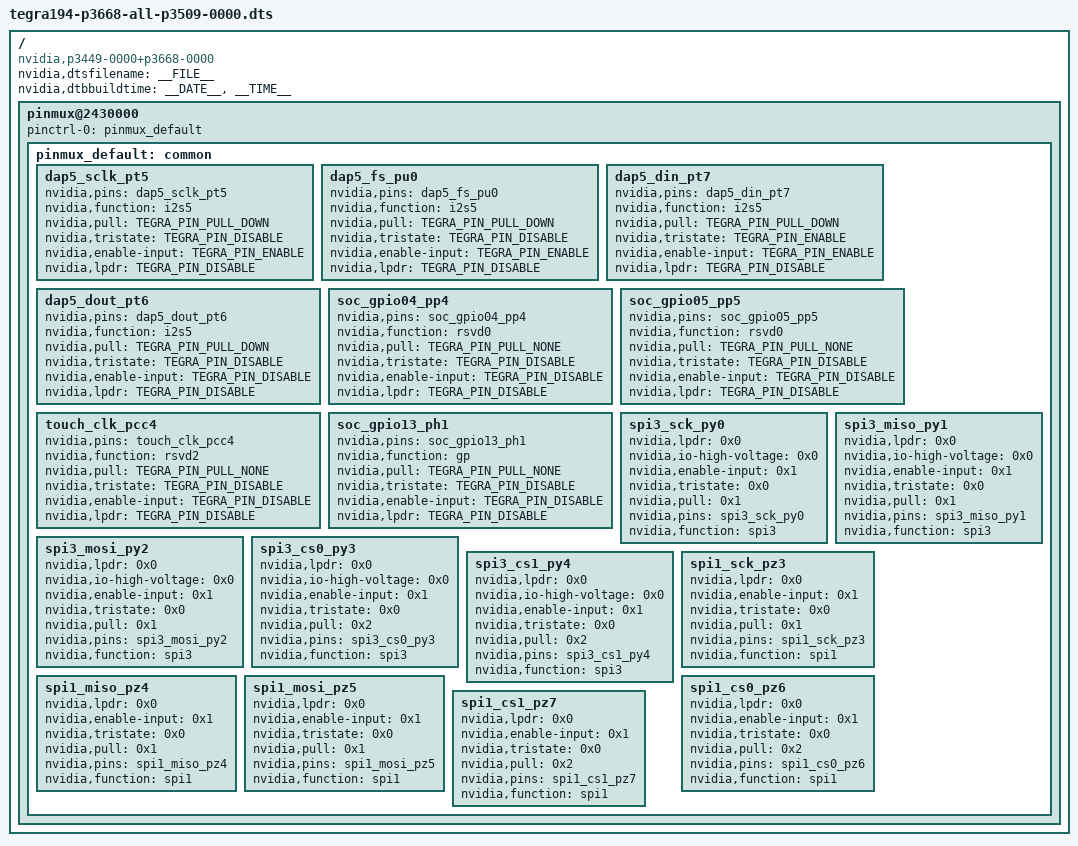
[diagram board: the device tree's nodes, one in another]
/*
 * Top level DTS file for CVM:P3668-0001 and CVB:P3509-0000.
 *
 * Copyright (c) 2019-2020, NVIDIA CORPORATION.  All rights reserved.
 *
 * This program is free software; you can redistribute it and/or modify
 * it under the terms of the GNU General Public License as published by
 * the Free Software Foundation; version 2 of the License.
 *
 * This program is distributed in the hope that it will be useful, but WITHOUT
 * ANY WARRANTY; without even the implied warranty of MERCHANTABILITY or
 * FITNESS FOR A PARTICULAR PURPOSE.  See the GNU General Public License for
 * more details.
 */

/dts-v1/;
#include "common/tegra194-p3668-common.dtsi"
#include "common/tegra194-p3509-0000-a00.dtsi"

/ {
	nvidia,dtsfilename = __FILE__;
	nvidia,dtbbuildtime = __DATE__, __TIME__;

	compatible = "nvidia,p3449-0000+p3668-0000", "nvidia,p3449-0000+p3668-0001", "nvidia,p3509-0000+p3668-0000", "nvidia,p3509-0000+p3668-0001", "nvidia,tegra194";
};

/* For EAC-2000, Why at here */
/ {
	
	pinmux@2430000 {
		pinctrl-names = "default", "drive", "unused";
		pinctrl-0 = <&pinmux_default>;
		
		pinmux_default: common {
			/* I2C0 (dap5 group) at Key E */
			dap5_sclk_pt5 {
				nvidia,pins = "dap5_sclk_pt5";
				nvidia,function = "i2s5";
				nvidia,pull = <TEGRA_PIN_PULL_DOWN>;
				nvidia,tristate = <TEGRA_PIN_DISABLE>;
				nvidia,enable-input = <TEGRA_PIN_ENABLE>;
				nvidia,lpdr = <TEGRA_PIN_DISABLE>;
			};

			dap5_fs_pu0 {
				nvidia,pins = "dap5_fs_pu0";
				nvidia,function = "i2s5";
				nvidia,pull = <TEGRA_PIN_PULL_DOWN>;
				nvidia,tristate = <TEGRA_PIN_DISABLE>;
				nvidia,enable-input = <TEGRA_PIN_ENABLE>;
				nvidia,lpdr = <TEGRA_PIN_DISABLE>;
			};
				
			dap5_din_pt7 {
				nvidia,pins = "dap5_din_pt7";
				nvidia,function = "i2s5";
				nvidia,pull = <TEGRA_PIN_PULL_DOWN>;
				nvidia,tristate = <TEGRA_PIN_ENABLE>;
				nvidia,enable-input = <TEGRA_PIN_ENABLE>;
				nvidia,lpdr = <TEGRA_PIN_DISABLE>;
			};

			dap5_dout_pt6 {
				nvidia,pins = "dap5_dout_pt6";
				nvidia,function = "i2s5";
				nvidia,pull = <TEGRA_PIN_PULL_DOWN>;
				nvidia,tristate = <TEGRA_PIN_DISABLE>;
				nvidia,enable-input = <TEGRA_PIN_DISABLE>;
				nvidia,lpdr = <TEGRA_PIN_DISABLE>;
			};

			/* CAM0_PWDN */
			soc_gpio04_pp4 {
				nvidia,pins = "soc_gpio04_pp4";
                                nvidia,function = "rsvd0";
				nvidia,pull = <TEGRA_PIN_PULL_NONE>;
				nvidia,tristate = <TEGRA_PIN_DISABLE>;
				nvidia,enable-input = <TEGRA_PIN_DISABLE>;
				nvidia,lpdr = <TEGRA_PIN_DISABLE>;
			};

			/* CAM1_PWDN */
			soc_gpio05_pp5 {
				nvidia,pins = "soc_gpio05_pp5";
				nvidia,function = "rsvd0";
				nvidia,pull = <TEGRA_PIN_PULL_NONE>;
				nvidia,tristate = <TEGRA_PIN_DISABLE>;
				nvidia,enable-input = <TEGRA_PIN_DISABLE>;
				nvidia,lpdr = <TEGRA_PIN_DISABLE>;
			};

			/* COM2 Mode - GPIO12_LS */
			touch_clk_pcc4 {
				nvidia,pins = "touch_clk_pcc4";
				nvidia,function = "rsvd2";
				nvidia,pull = <TEGRA_PIN_PULL_NONE>;
				nvidia,tristate = <TEGRA_PIN_DISABLE>;
				nvidia,enable-input = <TEGRA_PIN_DISABLE>;
				nvidia,lpdr = <TEGRA_PIN_DISABLE>;
			};

			/* FAN_PWM */ 
			soc_gpio13_ph1 {
				nvidia,pins = "soc_gpio13_ph1";
				nvidia,function = "gp";
				nvidia,pull = <TEGRA_PIN_PULL_NONE>;
				nvidia,tristate = <TEGRA_PIN_DISABLE>;
				nvidia,enable-input = <TEGRA_PIN_DISABLE>;
				nvidia,lpdr = <TEGRA_PIN_DISABLE>;
			};

			/* SPI1 Header */
			spi3_sck_py0 {
				nvidia,lpdr = <0x0>;
				nvidia,io-high-voltage = <0x0>;
				nvidia,enable-input = <0x1>;
				nvidia,tristate = <0x0>;
				nvidia,pull = <0x1>;
				nvidia,pins = "spi3_sck_py0";
				nvidia,function = "spi3";
			};

			spi3_miso_py1 {
				nvidia,lpdr = <0x0>;
				nvidia,io-high-voltage = <0x0>;
				nvidia,enable-input = <0x1>;
				nvidia,tristate = <0x0>;
				nvidia,pull = <0x1>;
				nvidia,pins = "spi3_miso_py1";
				nvidia,function = "spi3";
			};

			spi3_mosi_py2 {
				nvidia,lpdr = <0x0>;
				nvidia,io-high-voltage = <0x0>;
				nvidia,enable-input = <0x1>;
				nvidia,tristate = <0x0>;
				nvidia,pull = <0x1>;
				nvidia,pins = "spi3_mosi_py2";
				nvidia,function = "spi3";
			};

			spi3_cs0_py3 {
				nvidia,lpdr = <0x0>;
				nvidia,io-high-voltage = <0x0>;
				nvidia,enable-input = <0x1>;
				nvidia,tristate = <0x0>;
				nvidia,pull = <0x2>;
				nvidia,pins = "spi3_cs0_py3";
				nvidia,function = "spi3";
			};

			spi3_cs1_py4 {
				nvidia,lpdr = <0x0>;
				nvidia,io-high-voltage = <0x0>;
				nvidia,enable-input = <0x1>;
				nvidia,tristate = <0x0>;
				nvidia,pull = <0x2>;
				nvidia,pins = "spi3_cs1_py4";
				nvidia,function = "spi3";
			};

			/* SPI0 Header */
			spi1_sck_pz3 {
				nvidia,lpdr = <0x0>;
				nvidia,enable-input = <0x1>;
				nvidia,tristate = <0x0>;
				nvidia,pull = <0x1>;
				nvidia,pins = "spi1_sck_pz3";
				nvidia,function = "spi1";
			};

			spi1_miso_pz4 {
				nvidia,lpdr = <0x0>;
				nvidia,enable-input = <0x1>;
				nvidia,tristate = <0x0>;
				nvidia,pull = <0x1>;
				nvidia,pins = "spi1_miso_pz4";
				nvidia,function = "spi1";
			};

			spi1_mosi_pz5 {
				nvidia,lpdr = <0x0>;
				nvidia,enable-input = <0x1>;
				nvidia,tristate = <0x0>;
				nvidia,pull = <0x1>;
				nvidia,pins = "spi1_mosi_pz5";
				nvidia,function = "spi1";
			};

			spi1_cs0_pz6 {
				nvidia,lpdr = <0x0>;
				nvidia,enable-input = <0x1>;
				nvidia,tristate = <0x0>;
				nvidia,pull = <0x2>;
				nvidia,pins = "spi1_cs0_pz6";
				nvidia,function = "spi1";
			};

			spi1_cs1_pz7 {
				nvidia,lpdr = <0x0>;
				nvidia,enable-input = <0x1>;
				nvidia,tristate = <0x0>;
				nvidia,pull = <0x2>;
				nvidia,pins = "spi1_cs1_pz7";
				nvidia,function = "spi1";
			};
 		};
	};
};

